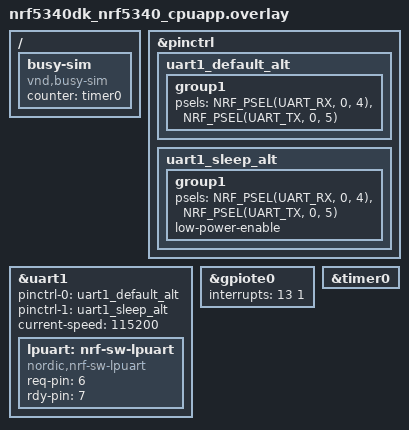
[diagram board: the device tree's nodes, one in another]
/*
 * Copyright (c) 2026 Nordic Semiconductor ASA
 *
 * SPDX-License-Identifier: LicenseRef-Nordic-5-Clause
 */

/* Two GPIO loopbacks are required:
 * Request-Response Pins: P0.06 - P0.07
 * UART RX-TX Pins: P0.04 - P0.05
 */

&pinctrl {
	uart1_default_alt: uart1_default_alt {
		group1 {
			psels = <NRF_PSEL(UART_RX, 0, 4)>,
				<NRF_PSEL(UART_TX, 0, 5)>;
		};
	};

	uart1_sleep_alt: uart1_sleep_alt {
		group1 {
			psels = <NRF_PSEL(UART_RX, 0, 4)>,
				<NRF_PSEL(UART_TX, 0, 5)>;
			low-power-enable;
		};
	};
};

&uart1 {
	status = "okay";
	pinctrl-0 = <&uart1_default_alt>;
	pinctrl-1 = <&uart1_sleep_alt>;
	pinctrl-names = "default", "sleep";
	current-speed = <115200>;

	lpuart: nrf-sw-lpuart {
		compatible = "nordic,nrf-sw-lpuart";
		status = "okay";
		req-pin = <6>; /* P0.06 */
		rdy-pin = <7>; /* P0.07 */
	};
};

&gpiote0 {
	status = "okay";
	interrupts = <13 1>;
};

&timer0 {
	status = "okay";
};

/ {
	busy-sim {
		compatible = "vnd,busy-sim";
		status = "okay";
		counter = <&timer0>;
	};
};
